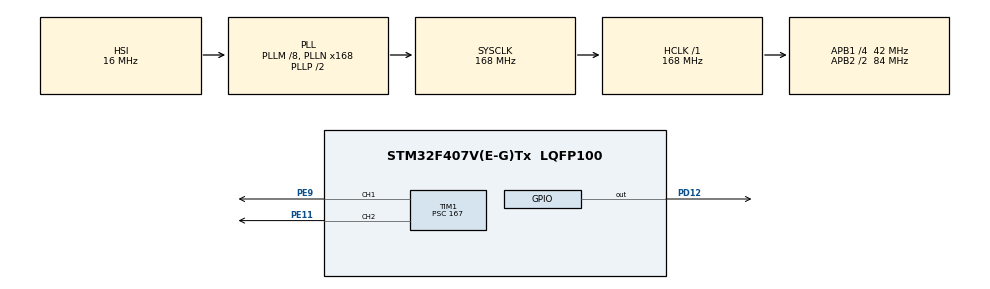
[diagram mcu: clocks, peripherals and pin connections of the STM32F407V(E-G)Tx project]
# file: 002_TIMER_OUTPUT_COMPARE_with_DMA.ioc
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Dma.Request0=TIM1_CH1
Dma.TIM1_CH1.0.Direction=DMA_MEMORY_TO_PERIPH
Dma.TIM1_CH1.0.FIFOMode=DMA_FIFOMODE_DISABLE
Dma.TIM1_CH1.0.Instance=DMA2_Stream1
Dma.TIM1_CH1.0.MemDataAlignment=DMA_MDATAALIGN_HALFWORD
Dma.TIM1_CH1.0.MemInc=DMA_MINC_ENABLE
Dma.TIM1_CH1.0.Mode=DMA_CIRCULAR
Dma.TIM1_CH1.0.PeriphDataAlignment=DMA_PDATAALIGN_HALFWORD
Dma.TIM1_CH1.0.PeriphInc=DMA_PINC_DISABLE
Dma.TIM1_CH1.0.Priority=DMA_PRIORITY_LOW
Mcu.Family=STM32F4
Mcu.Name=STM32F407V(E-G)Tx
Mcu.Package=LQFP100
NVIC.DMA2_Stream1_IRQn=true\:0\:0\:false\:false\:true\:false\:true
NVIC.PriorityGroup=NVIC_PRIORITYGROUP_0
NVIC.TIM1_CC_IRQn=true\:0\:0\:false\:false\:true\:true\:true
NVIC.TIM1_UP_TIM10_IRQn=true\:0\:0\:false\:false\:true\:true\:true
PD12.Signal=GPIO_Output
PE11.Signal=S_TIM1_CH2
PE9.Signal=S_TIM1_CH1
PH0-OSC_IN.Mode=HSE-External-Oscillator
PH0-OSC_IN.Signal=RCC_OSC_IN
PH1-OSC_OUT.Mode=HSE-External-Oscillator
PH1-OSC_OUT.Signal=RCC_OSC_OUT
ProjectManager.HeapSize=0x200
ProjectManager.StackSize=0x400
ProjectManager.TargetToolchain=STM32CubeIDE
RCC.48MHZClocksFreq_Value=48000000
RCC.AHBFreq_Value=168000000
RCC.APB1CLKDivider=RCC_HCLK_DIV4
RCC.APB1Freq_Value=42000000
RCC.APB1TimFreq_Value=84000000
RCC.APB2CLKDivider=RCC_HCLK_DIV2
RCC.APB2Freq_Value=84000000
RCC.APB2TimFreq_Value=168000000
RCC.CortexFreq_Value=168000000
RCC.HCLKFreq_Value=168000000
RCC.HSE_VALUE=8000000
RCC.HSI_VALUE=16000000
RCC.LSE_VALUE=32768
RCC.PLLM=8
RCC.PLLN=168
RCC.PLLQ=7
RCC.SYSCLKFreq_VALUE=168000000
RCC.SYSCLKSource=RCC_SYSCLKSOURCE_PLLCLK
RCC.VCOOutputFreq_Value=336000000
SH.S_TIM1_CH1.0=TIM1_CH1,Output Compare1 CH1
SH.S_TIM1_CH2.0=TIM1_CH2,Output Compare2 CH2
TIM1.Channel-Output\ Compare1\ CH1=TIM_CHANNEL_1
TIM1.Channel-Output\ Compare2\ CH2=TIM_CHANNEL_2
TIM1.OCMode_1=TIM_OCMODE_TOGGLE
TIM1.OCMode_2=TIM_OCMODE_TOGGLE
TIM1.Period=10000
TIM1.Prescaler=167
TIM1.Pulse-Output\ Compare1\ CH1=4999
TIM1.Pulse-Output\ Compare2\ CH2=9999
board=STM32F407G-DISC1

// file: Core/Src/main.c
/* USER CODE BEGIN Header */
/**
  ******************************************************************************
  * @file           : main.c
  * @brief          : Main program body
  ******************************************************************************
  * @attention
  *
  * Copyright (c) 2021 STMicroelectronics.
  * All rights reserved.
  *
  * This software is licensed under terms that can be found in the LICENSE file
  * in the root directory of this software component.
  * If no LICENSE file comes with this software, it is provided AS-IS.
  *
  ******************************************************************************
  */
/* USER CODE END Header */
#include "main.h"

TIM_HandleTypeDef htim1;
DMA_HandleTypeDef hdma_tim1_ch1;

/* USER CODE BEGIN PV */
const uint16_t ch1IV[] = {50,200,500,1100,2000}; // 50 , 150, 300 , 600 , 900 width pulses
volatile uint16_t CH1_FREQ = 0;
volatile uint16_t CH2_FREQ = 0;
/* USER CODE END PV */

void SystemClock_Config(void);
static void MX_GPIO_Init(void);
static void MX_DMA_Init(void);
static void MX_TIM1_Init(void);

/* USER CODE BEGIN 0 */
uint16_t computePulse(TIM_HandleTypeDef *htim, uint32_t chFrequency) {
  uint32_t timFrequency= HAL_RCC_GetPCLK1Freq() / (htim->Instance->PSC + 1);

  return (uint16_t)(timFrequency / chFrequency);
}
/* USER CODE END 0 */

int main(void)
{

  /* MCU Configuration--------------------------------------------------------*/

  /* Reset of all peripherals, Initializes the Flash interface and the Systick. */
  HAL_Init();

  /* Configure the system clock */
  SystemClock_Config();

  /* Initialize all configured peripherals */
  MX_GPIO_Init();
  MX_DMA_Init();
  MX_TIM1_Init();
  /* USER CODE BEGIN 2 */
  //HAL_TIM_OC_Start_IT(&htim1, TIM_CHANNEL_1);
  HAL_TIM_OC_Start_DMA(&htim1, TIM_CHANNEL_1, (uint32_t)ch1IV, sizeof(ch1IV));

  /* USER CODE END 2 */

  /* Infinite loop */
  while (1)
  {

  }
}

void SystemClock_Config(void)
{
  RCC_OscInitTypeDef RCC_OscInitStruct = {0};
  RCC_ClkInitTypeDef RCC_ClkInitStruct = {0};

  /** Configure the main internal regulator output voltage
  */
  __HAL_RCC_PWR_CLK_ENABLE();
  __HAL_PWR_VOLTAGESCALING_CONFIG(PWR_REGULATOR_VOLTAGE_SCALE1);
  /** Initializes the RCC Oscillators according to the specified parameters
  * in the RCC_OscInitTypeDef structure.
  */
  RCC_OscInitStruct.OscillatorType = RCC_OSCILLATORTYPE_HSI;
  RCC_OscInitStruct.HSIState = RCC_HSI_ON;
  RCC_OscInitStruct.HSICalibrationValue = RCC_HSICALIBRATION_DEFAULT;
  RCC_OscInitStruct.PLL.PLLState = RCC_PLL_ON;
  RCC_OscInitStruct.PLL.PLLSource = RCC_PLLSOURCE_HSI;
  RCC_OscInitStruct.PLL.PLLM = 8;
  RCC_OscInitStruct.PLL.PLLN = 168;
  RCC_OscInitStruct.PLL.PLLP = RCC_PLLP_DIV2;
  RCC_OscInitStruct.PLL.PLLQ = 7;
  if (HAL_RCC_OscConfig(&RCC_OscInitStruct) != HAL_OK)
  {
    Error_Handler();
  }
  /** Initializes the CPU, AHB and APB buses clocks
  */
  RCC_ClkInitStruct.ClockType = RCC_CLOCKTYPE_HCLK|RCC_CLOCKTYPE_SYSCLK
                              |RCC_CLOCKTYPE_PCLK1|RCC_CLOCKTYPE_PCLK2;
  RCC_ClkInitStruct.SYSCLKSource = RCC_SYSCLKSOURCE_PLLCLK;
  RCC_ClkInitStruct.AHBCLKDivider = RCC_SYSCLK_DIV1;
  RCC_ClkInitStruct.APB1CLKDivider = RCC_HCLK_DIV4;
  RCC_ClkInitStruct.APB2CLKDivider = RCC_HCLK_DIV2;

  if (HAL_RCC_ClockConfig(&RCC_ClkInitStruct, FLASH_LATENCY_5) != HAL_OK)
  {
    Error_Handler();
  }
}

static void MX_TIM1_Init(void)
{

  TIM_MasterConfigTypeDef sMasterConfig = {0};
  TIM_OC_InitTypeDef sConfigOC = {0};
  TIM_BreakDeadTimeConfigTypeDef sBreakDeadTimeConfig = {0};

  htim1.Instance = TIM1;
  htim1.Init.Prescaler = 167;
  htim1.Init.CounterMode = TIM_COUNTERMODE_UP;
  htim1.Init.Period = 10000;
  htim1.Init.ClockDivision = TIM_CLOCKDIVISION_DIV1;
  htim1.Init.RepetitionCounter = 0;
  htim1.Init.AutoReloadPreload = TIM_AUTORELOAD_PRELOAD_DISABLE;
  if (HAL_TIM_OC_Init(&htim1) != HAL_OK)
  {
    Error_Handler();
  }
  sMasterConfig.MasterOutputTrigger = TIM_TRGO_RESET;
  sMasterConfig.MasterSlaveMode = TIM_MASTERSLAVEMODE_DISABLE;
  if (HAL_TIMEx_MasterConfigSynchronization(&htim1, &sMasterConfig) != HAL_OK)
  {
    Error_Handler();
  }
  sConfigOC.OCMode = TIM_OCMODE_TOGGLE;
  sConfigOC.Pulse = 4999;
  sConfigOC.OCPolarity = TIM_OCPOLARITY_HIGH;
  sConfigOC.OCNPolarity = TIM_OCNPOLARITY_HIGH;
  sConfigOC.OCFastMode = TIM_OCFAST_DISABLE;
  sConfigOC.OCIdleState = TIM_OCIDLESTATE_RESET;
  sConfigOC.OCNIdleState = TIM_OCNIDLESTATE_RESET;
  if (HAL_TIM_OC_ConfigChannel(&htim1, &sConfigOC, TIM_CHANNEL_1) != HAL_OK)
  {
    Error_Handler();
  }
  sConfigOC.Pulse = 9999;
  if (HAL_TIM_OC_ConfigChannel(&htim1, &sConfigOC, TIM_CHANNEL_2) != HAL_OK)
  {
    Error_Handler();
  }
  sBreakDeadTimeConfig.OffStateRunMode = TIM_OSSR_DISABLE;
  sBreakDeadTimeConfig.OffStateIDLEMode = TIM_OSSI_DISABLE;
  sBreakDeadTimeConfig.LockLevel = TIM_LOCKLEVEL_OFF;
  sBreakDeadTimeConfig.DeadTime = 0;
  sBreakDeadTimeConfig.BreakState = TIM_BREAK_DISABLE;
  sBreakDeadTimeConfig.BreakPolarity = TIM_BREAKPOLARITY_HIGH;
  sBreakDeadTimeConfig.AutomaticOutput = TIM_AUTOMATICOUTPUT_DISABLE;
  if (HAL_TIMEx_ConfigBreakDeadTime(&htim1, &sBreakDeadTimeConfig) != HAL_OK)
  {
    Error_Handler();
  }
  HAL_TIM_MspPostInit(&htim1);

}

static void MX_DMA_Init(void)
{

  /* DMA controller clock enable */
  __HAL_RCC_DMA2_CLK_ENABLE();

  /* DMA interrupt init */
  /* DMA2_Stream1_IRQn interrupt configuration */
  HAL_NVIC_SetPriority(DMA2_Stream1_IRQn, 0, 0);
  HAL_NVIC_EnableIRQ(DMA2_Stream1_IRQn);

}

static void MX_GPIO_Init(void)
{
  GPIO_InitTypeDef GPIO_InitStruct = {0};

  /* GPIO Ports Clock Enable */
  __HAL_RCC_GPIOH_CLK_ENABLE();
  __HAL_RCC_GPIOE_CLK_ENABLE();
  __HAL_RCC_GPIOD_CLK_ENABLE();

  /*Configure GPIO pin Output Level */
  HAL_GPIO_WritePin(GPIOD, GPIO_PIN_12, GPIO_PIN_RESET);

  /*Configure GPIO pin : PD12 */
  GPIO_InitStruct.Pin = GPIO_PIN_12;
  GPIO_InitStruct.Mode = GPIO_MODE_OUTPUT_PP;
  GPIO_InitStruct.Pull = GPIO_NOPULL;
  GPIO_InitStruct.Speed = GPIO_SPEED_FREQ_LOW;
  HAL_GPIO_Init(GPIOD, &GPIO_InitStruct);

}

/* USER CODE BEGIN 4 */
void HAL_TIM_OC_DelayElapsedCallback(TIM_HandleTypeDef *htim) {
  uint32_t pulse;

  /* TIMx_CH1 toggling with frequency = 50KHz */
  if(htim->Channel == HAL_TIM_ACTIVE_CHANNEL_1)
  {
    pulse = HAL_TIM_ReadCapturedValue(htim, TIM_CHANNEL_1);
    /* Set the Capture Compare Register value */
    __HAL_TIM_SET_COMPARE(htim, TIM_CHANNEL_1, (pulse + CH1_FREQ));
  }

  /* TIM2_CH2 toggling with frequency = 100KHz */
  if(htim->Channel == HAL_TIM_ACTIVE_CHANNEL_2)
  {
    pulse = HAL_TIM_ReadCapturedValue(htim, TIM_CHANNEL_2);
    /* Set the Capture Compare Register value */
    __HAL_TIM_SET_COMPARE(htim, TIM_CHANNEL_2, (pulse + CH2_FREQ));
  }
}
void HAL_TIM_PeriodElapsedCallback(TIM_HandleTypeDef *htim) {
  if(htim->Instance == TIM1)
    HAL_GPIO_TogglePin(GPIOD, GPIO_PIN_12);
}
/* USER CODE END 4 */

void Error_Handler(void)
{
  __disable_irq();
  while (1)
  {
  }
}
